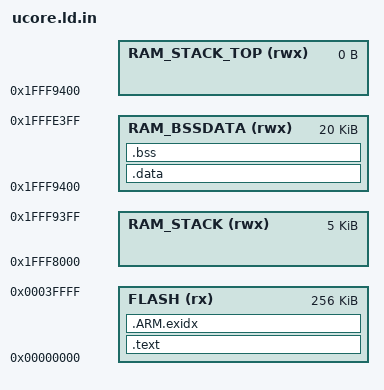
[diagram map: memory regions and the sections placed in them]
OUTPUT_FORMAT("elf32-littlearm", "elf32-bigarm", "elf32-littlearm")
OUTPUT_ARCH(arm)

MEMORY
{
  RAM_BSSDATA   (rwx) : ORIGIN = 0x1FFF9400, LENGTH = 0x5000   /*   20k */   /* Remain 20k for .data and .bss */
  RAM_STACK_TOP (rwx) : ORIGIN = 0x1FFF9400, LENGTH = 0x0000
  RAM_STACK     (rwx) : ORIGIN = 0x1FFF8000, LENGTH = 0x1400   /*   5k */    /* Set stack size as 5k. */
  FLASH         (rx)  : ORIGIN = 0x00000000, LENGTH = 0x40000   /* 512K   .text stay here  */
}

ENTRY(reset_handler)

SECTIONS {
	.text : 
	{
		*(.vector)
		PROVIDE(__kernel_text_start = .);
		*(.text)
		PROVIDE(__kernel_text_end = .);
		*(.rodata)
		PROVIDE(__start___param = .);
       		*(__param)
       	 	PROVIDE(__stop___param = .);
        	PROVIDE(__start___ksymtab = .);
        	PROVIDE(__stop___ksymtab = .);
        	PROVIDE(__start___ksymtab_gpl = .);
        	PROVIDE(__stop___ksymtab_gpl = .);
		*(__ksymtab)
        	*(__ksymtab_strings)
		*(.ARM.extab)
	} > FLASH
	
    __exidx_start = .;
    .ARM.exidx :
    {
        *(.ARM.exidx* .gnu.linkonce.armexidx.*)
    } > FLASH
    __exidx_end = .;
    		
	__data_org = .;
	.data : AT(__data_org) 
	{
		__data_start = .;
		*(.data)
		__data_end = .;
		PROVIDE(__percpu_start = .);   /*Put here or the bss section or something else? At least not flash!*/
                *(.percpu)
                PROVIDE(__percpu_end = .);
	} > RAM_BSSDATA
	.bss : 
	{
		 __bss_start = .;
                PROVIDE (__noinit_start = .);
                *(.noinit)
                PROVIDE (__noinit_end = .);
                *(.bss)
                *(COMMON)
                __bss_end = .;
                __end = .;	
		PROVIDE(end = .); /* Define the 'end' symbol to this value */
	} > RAM_BSSDATA		/*unsafe*/
	
    __stack_top = ORIGIN(RAM_STACK_TOP);

    PROVIDE(etext = .); /* Define the 'etext' symbol to this value */
    PROVIDE(edata = .); /* Define the 'edata' symbol to this value */
    PROVIDE(__STAB_BEGIN__ = .);
    PROVIDE(__STAB_END__ = .);
    PROVIDE(__STABSTR_BEGIN__ = .);
    PROVIDE(__STABSTR_END__ = .);
 
   /DISCARD/ :
    {
        *(.eh_*)
    }
}
